# headsail register map
Vendor: tuni.fi; File version: 1.1
CPU: other r1p0, little endian, no MPU, no FPU, vendor SysTick, 2 interrupt priority bits
Registers are 32-bit, read-write, no defined reset value unless marked. A register's access mark holds for its fields unless they carry their own. Offsets are from the block's base; [hi:lo] are bit positions; lines under a group give offsets from that group; {n}, {i} and the like mark numbered series.

## HPC
Base 0x1FFE00000
0x50000 timer group
  {0x0+0xC*j} timer{j}_timer ro (j=0..2) — Monotonically increasing timer register for timer {j}
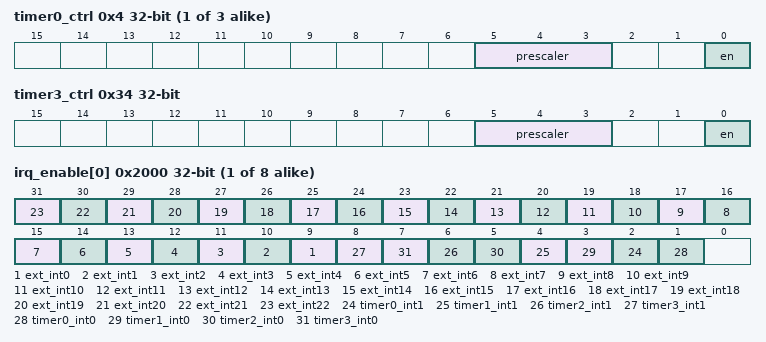
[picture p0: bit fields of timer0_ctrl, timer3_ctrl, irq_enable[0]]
  {0x4+0xC*j} timer{j}_ctrl (j=0..2) — Control register for timer {j}
    [5:3] prescaler — Prescaler bits
    [0] en — Enable timer
  {0x8+0xC*j} timer{j}_cmp (j=0..2) — Timer compare register for timer {j}. Writing this will zero timer register for timer {j}.
  0x30 timer3_timer ro — Monotonically increasing timer register for timer 3
  0x34 timer3_ctrl — Control register for timer 3
    [5:3] prescaler — Prescaler bits
    [0] en — Enable timer
  0x38 timer3_cmp — Timer compare register for timer 3. Writing this will zero timer register for timer 3.
0x52000 l2_config group
  0x00 en 64-bit — Enable L2 cache
    [0] en
      0=disabled; 1=enabled
0x54000 cluster_config group
  {0x0+8j} core{j}_boot_addr 64-bit reset 0x10000 (j=0..3) — Core #{j} boot address
    [63:0] boot_addr
  0x20 core0_hart_id 64-bit ro reset 0x0
    [63:0] hart_id
  0x28 core1_hart_id 64-bit ro reset 0x1
    [63:0] hart_id
  0x30 core2_hart_id 64-bit ro reset 0x2
    [63:0] hart_id
  0x38 core3_hart_id 64-bit ro reset 0x3
    [63:0] hart_id
  0x40 rtc_cfg0 64-bit reset 0xDFA20018A — Real-time clock generator clock high count
    [63:0] cfg
  0x48 rtc_cfg1 64-bit reset 0x5F5E1000324 — Real-time clock generator clock low count
    [63:0] cfg
  0x50 rtc_cfg2 64-bit reset 0x1 — Real-time clock generator clock fine tune
    [63:0] cfg
  0x68 timer_base 64-bit reset 0x50000
  0x70 timer_len 64-bit reset 0x1000
  0x78 plic_base 64-bit reset 0x80000
  0x80 plic_len 64-bit reset 0x10000
  0x88 clint_base 64-bit reset 0x60000
  0x90 clint_len 64-bit reset 0x10000
  0x98 rom_base 64-bit reset 0x10000
  0xA0 rom_len 64-bit reset 0x8000
  0xA8 debug_base 64-bit reset 0x0
  0xB0 debug_len 64-bit reset 0x1000
  0xB8 l2_config_base 64-bit reset 0x52000
  0xC0 l2_config_len 64-bit reset 0x1000
  0xC8 cluster_config_base 64-bit reset 0x54000
  0xD0 cluster_config_len 64-bit reset 0x1000
  0xD8 external_memory_base 64-bit reset 0x100000000 — Original memory map calls this dram_base_addr but the register has been repurposed
  0xE0 external_memory_len 64-bit reset 0x1000000000 — Original memory map calls this dram_addr_length but the register has been repurposed
  0xE8 addr_valid_rule 64-bit reset 0x1 — Valid address space flags
  0xF0 nr_exec_regions 64-bit reset 0x2 — Number of execute regions
    [63:0] nr
  {0xF8+0x10*j} execute_region_addr_base{j} 64-bit (j=0..7) — Base address for execute region #{j}
    [63:0] base
  {0x100+0x10*j} execute_region_length{j} 64-bit (j=0..5) — Length for execute region #{j}
    [63:0] len
  0x160 execute_region_length6 64-bit — Length for execute region #6
    [63:0] len_0
  0x170 execute_region_length7 64-bit — Length for execute region #7
    [63:0] len
  0x178 nr_cached_regions 64-bit reset 0x0 — Number of cached regions
    [63:0] nr
  0x180 cached_region_addr_base0 64-bit reset 0x0 — Base address for cached region #0 There are 8x 64-bit cached region base address registers (0..=7), spaced 0x10 bytes from each other.
    [63:0] base — Base address for cached region #[%s]
  0x188 cached_region_addr_length0 64-bit — Length for cached region #0 There are 8x 64-bit cached region length registers (0..=7), spaced 0x10 bytes from each other.
    [63:0] len
  0x200 nr_non_idempotent_regions 64-bit — Number of regions with side-effects
    [63:0] nr
  0x208 non_idempotent_region_addr_base0 64-bit — Base address for non-idempotent (side-effectful) region #0 There are 4x 64-bit non-idempotent region base address registers (0..=3), spaced 0x10 bytes from each other.
    [63:0] base — Base address for side-effectful region #[%s]
  0x210 non_idempotent_region_length0 64-bit — Length for non-idempotent (side-effectful) region #0 There are 4x 64-bit non-idempotent region length registers (0..=3), spaced 0x10 bytes from each other.
    [63:0] len
  0x248 l2_div 64-bit reset 0x1
  0x250 power_switch_en 64-bit
    [0] en
      1=enabled; 0=disabled
  0x258 power_switch_ack 64-bit ro
0x60000 clint group
  {0x0+8j} msip[{j}] (j=0..3) 64-bit reset 0x0 — Array of machine mode software interrupts (IPI) for all Harts Machine-mode software interrupts are generated by writing to msip. Software interrupts are commonly usde for interprocessor communication. This is usually done by one Hart writing into another Harts msip register.
    [0] msip
  {0x4000+8j} mtimecmp[{j}] (j=0..3) 64-bit — Array of machine mode timer compare registers for all Harts A timer interrupt for Hart #n is signalled whenever mtime is greater than or equal to the value in mtimecmp[n]. The timer interrupt is reflected in mtip bit of the mip register.
    [63:0] mtimecmp
  0xBFF8 mtime 64-bit — Cycle counter. A timer interrupt for Hart #n is signalled whenever mtime is greater than or equal to the value in mtimecmp[n]. The timer interrupt is reflected in mtip bit of the mip register.
0x80000 plic group
  0x00 base ro — Reserved
  {0x4+4j} timer0_prio[{j}] (j=0..1) — Interrupt priority for timer 0 interrupt [{j}] (timer overflow interrupt). Max priority is 7.
    [31:0] prio
  {0xC+4j} timer1_prio[{j}] (j=0..1) — Interrupt priority for timer 1 interrupt [{j}] (timer overflow interrupt). Max priority is 7.
    [31:0] prio
  {0x14+4j} timer2_prio[{j}] (j=0..1) — Interrupt priority for timer 2 interrupt [{j}] (timer overflow interrupt). Max priority is 7.
    [31:0] prio
  {0x1C+4j} timer3_prio[{j}] (j=0..1) — Interrupt priority for timer 3 interrupt [{j}] (timer overflow interrupt). Max priority is 7.
    [31:0] prio
  {0x24+4j} ext_prio[{j}] (j=0..22) — Interrupt priority for external interrupt [{j}]
    [31:0] prio
  {0x2000+4j} irq_enable[{j}] (j=0..7) — IRQ enable bits for Hart context #[{j}]. `idx / 2` is core-#. Even indices are M-mode, odd indices are S-mode.
    [n+9] ext_int{n} (n=0..22), [2n+2] timer{n}_int1 (n=0..3), [2n+1] timer{n}_int0 (n=0..3)
  0x4000 prio_thr_0 reset 0x0 (reset mask 0xFFFFFFF8) — Priority threshold for Hart 0 M-Mode (context #0) HPC masks all PLIC interrupts of a priority less than or equal to threshold. E.g., threshold zero permits all interrupts with non-zero priority, while 7 masks all interrupts.
    [2:0] thr
  0x4004 claim_complete_0 — Claim/complete for Hart 0 M-mode (context #0) Read performs 'claim', which returns the ID of the highest-priority pending interrupt or zero if there is no pending interrupts. A successful claim also atomically clears the corresponding pending bit on the interrupt source. A 'complete' is performed by writing the received interrupt ID back into claim/complete, once an interrupt handler has been completed. If the completion ID does not match an interrupt source that is currently enabled for the target, the completion is silently ignored.
    [31:0] claim_complete
  0x5000 prio_thr_1 reset 0x0 (reset mask 0xFFFFFFF8) — Priority threshold for Hart 0 S-Mode (context #1) HPC masks all PLIC interrupts of a priority less than or equal to threshold. E.g., threshold zero permits all interrupts with non-zero priority, while 7 masks all interrupts.
    [2:0] thr
  0x5004 claim_complete_1 — Claim/complete for Hart 0 S-mode (context #1) Read performs 'claim', which returns the ID of the highest-priority pending interrupt or zero if there is no pending interrupts. A successful claim also atomically clears the corresponding pending bit on the interrupt source. A 'complete' is performed by writing the received interrupt ID back into claim/complete, once an interrupt handler has been completed. If the completion ID does not match an interrupt source that is currently enabled for the target, the completion is silently ignored.
    [31:0] claim_complete
  0x6000 prio_thr_2 reset 0x0 (reset mask 0xFFFFFFF8) — Priority threshold for Hart 1 M-Mode (context #2) HPC masks all PLIC interrupts of a priority less than or equal to threshold. E.g., threshold zero permits all interrupts with non-zero priority, while 7 masks all interrupts.
    [2:0] thr
  0x6004 claim_complete_2 — Claim/complete for Hart 1 M-mode (context #2) Read performs 'claim', which returns the ID of the highest-priority pending interrupt or zero if there is no pending interrupts. A successful claim also atomically clears the corresponding pending bit on the interrupt source. A 'complete' is performed by writing the received interrupt ID back into claim/complete, once an interrupt handler has been completed. If the completion ID does not match an interrupt source that is currently enabled for the target, the completion is silently ignored.
    [31:0] claim_complete
  0x7000 prio_thr_3 reset 0x0 (reset mask 0xFFFFFFF8) — Priority threshold for Hart 1 S-Mode (context #3) HPC masks all PLIC interrupts of a priority less than or equal to threshold. E.g., threshold zero permits all interrupts with non-zero priority, while 7 masks all interrupts.
    [2:0] thr
  0x7004 claim_complete_3 — Claim/complete for Hart 1 S-mode (context #3) Read performs 'claim', which returns the ID of the highest-priority pending interrupt or zero if there is no pending interrupts. A successful claim also atomically clears the corresponding pending bit on the interrupt source. A 'complete' is performed by writing the received interrupt ID back into claim/complete, once an interrupt handler has been completed. If the completion ID does not match an interrupt source that is currently enabled for the target, the completion is silently ignored.
    [31:0] claim_complete
  0x8000 prio_thr_4 reset 0x0 (reset mask 0xFFFFFFF8) — Priority threshold for Hart 2 M-Mode (context #4) HPC masks all PLIC interrupts of a priority less than or equal to threshold. E.g., threshold zero permits all interrupts with non-zero priority, while 7 masks all interrupts.
    [2:0] thr
  0x8004 claim_complete_4 — Claim/complete for Hart 2 M-mode (context #4) Read performs 'claim', which returns the ID of the highest-priority pending interrupt or zero if there is no pending interrupts. A successful claim also atomically clears the corresponding pending bit on the interrupt source. A 'complete' is performed by writing the received interrupt ID back into claim/complete, once an interrupt handler has been completed. If the completion ID does not match an interrupt source that is currently enabled for the target, the completion is silently ignored.
    [31:0] claim_complete
  0x9000 prio_thr_5 reset 0x0 (reset mask 0xFFFFFFF8) — Priority threshold for Hart 2 S-Mode (context #5) HPC masks all PLIC interrupts of a priority less than or equal to threshold. E.g., threshold zero permits all interrupts with non-zero priority, while 7 masks all interrupts.
    [2:0] thr
  0x9004 claim_complete_5 — Claim/complete for Hart 2 S-Mode (context #5) Read performs 'claim', which returns the ID of the highest-priority pending interrupt or zero if there is no pending interrupts. A successful claim also atomically clears the corresponding pending bit on the interrupt source. A 'complete' is performed by writing the received interrupt ID back into claim/complete, once an interrupt handler has been completed. If the completion ID does not match an interrupt source that is currently enabled for the target, the completion is silently ignored.
    [31:0] claim_complete
  0xA000 prio_thr_6 reset 0x0 (reset mask 0xFFFFFFF8) — Priority threshold for Hart 3 M-Mode (context #6) HPC masks all PLIC interrupts of a priority less than or equal to threshold. E.g., threshold zero permits all interrupts with non-zero priority, while 7 masks all interrupts.
    [2:0] thr
  0xA004 claim_complete_6 — Claim/complete for Hart 3 M-mode (context #6) Read performs 'claim', which returns the ID of the highest-priority pending interrupt or zero if there is no pending interrupts. A successful claim also atomically clears the corresponding pending bit on the interrupt source. A 'complete' is performed by writing the received interrupt ID back into claim/complete, once an interrupt handler has been completed. If the completion ID does not match an interrupt source that is currently enabled for the target, the completion is silently ignored.
    [31:0] claim_complete
  0xB000 prio_thr_7 reset 0x0 (reset mask 0xFFFFFFF8) — Priority threshold for Hart 3 S-Mode (context #7) HPC masks all PLIC interrupts of a priority less than or equal to threshold. E.g., threshold zero permits all interrupts with non-zero priority, while 7 masks all interrupts.
    [2:0] thr
  0xB004 claim_complete_7 — Claim/complete for Hart 3 S-mode (context #7) Read performs 'claim', which returns the ID of the highest-priority pending interrupt or zero if there is no pending interrupts. A successful claim also atomically clears the corresponding pending bit on the interrupt source. A 'complete' is performed by writing the received interrupt ID back into claim/complete, once an interrupt handler has been completed. If the completion ID does not match an interrupt source that is currently enabled for the target, the completion is silently ignored.
    [31:0] claim_complete
